# STM32WB05 register map
File version: 1.0
CPU: CM0+ r0p0, little endian, MPU, no FPU, 2 interrupt priority bits
Registers are 32-bit, read-write, reset 0x0 unless marked. A register's access mark holds for its fields unless they carry their own. Offsets are from the block's base; [hi:lo] are bit positions; {n}, {i} and the like mark numbered series.

## DMAMUX
Base 0x48800000
{0x0+4i} C{i}CR (i=0..7) (reset mask 0xF) — CxCR register
  [4:0] DMAREQ_ID — DMAREQ_ID[4:0]: DMA REQuest IDentification Selects the input DMA request. C.f. the DMAMUX table about assignments of multiplexer inputs to resources.
    2=Spi3Rx; 3=Spi3Tx; 8=I2c1Rx; 9=I2c1Tx; 12=UsartRx; 13=UsartTx; 14=LpuartRx; 15=LpuartTx; 16=ADC_CH0 (DS channel); {v}=Tim2Ch{v-17} (v=18..21); 22=Tim2Up; 23=Tim16Ch1; 24=Tim16Up; 25=Tim17Ch1; 26=Tim17Up

## GPIOA
Base 0x48000000
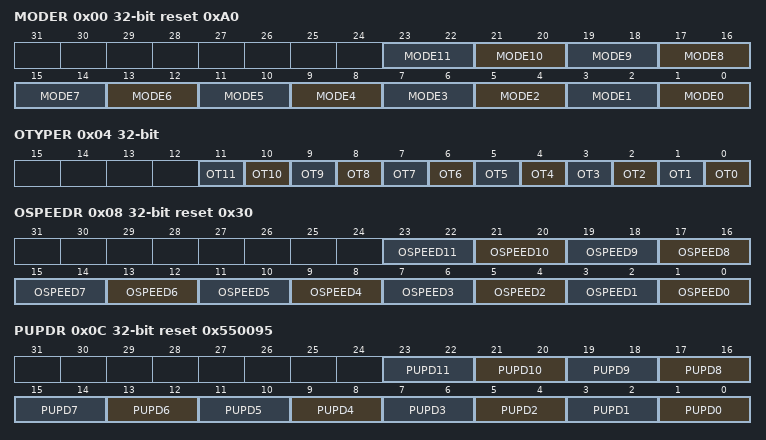
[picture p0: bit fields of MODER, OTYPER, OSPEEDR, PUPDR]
0x00 MODER reset 0xA0
  [2n+1:2n] MODE{n} (n=0..11) — Port x configuration pin {n}
    0=Input mode; 1=Output (General purpose output mode); 2=Alternate function mode; 3=Analog mode
0x04 OTYPER
  [n] OT{n} (n=0..11) — Port x configuration pin {n}
    0=PushPull (Output push-pull (reset state)); 1=OpenDrain (Output open-drain)
0x08 OSPEEDR reset 0x30
  [2n+1:2n] OSPEED{n} (n=0..11) — Port x configuration pin {n}
    0=LowSpeed; 1=MediumSpeed; 2=HighSpeed; 3=VeryHighSpeed
0x0C PUPDR reset 0x550095
  [2n+1:2n] PUPD{n} (n=0..11) — Port x configuration pin {n}
    0=Floating (No pull-up, pull-down); 1=PullUp; 2=PullDown
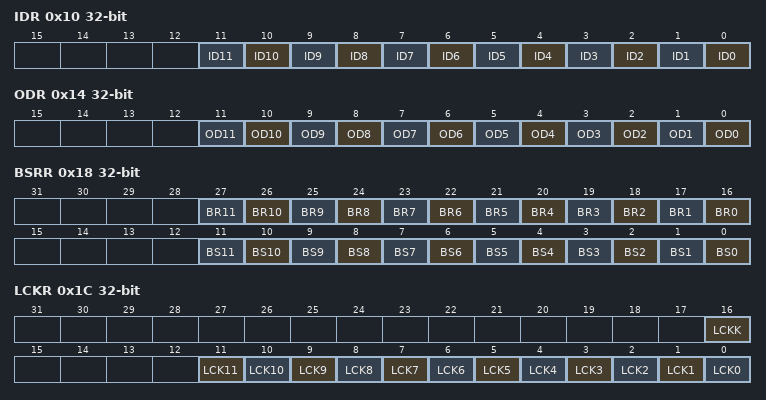
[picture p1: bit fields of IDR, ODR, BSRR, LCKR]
0x10 IDR ro
  [n] ID{n} (n=0..11) — Port input data pin {n}
    0=Low (Input is logic low); 1=High (Input is logic high)
0x14 ODR
  [n] OD{n} (n=0..11) — Port output data pin {n}
    0=Low (Set output to logic low); 1=High (Set output to logic high)
0x18 BSRR
  [n+16] BR{n} (n=0..11) wo — Port x reset pin {n}
    1=Resets the corresponding ODx bit
  [n] BS{n} (n=0..11) wo — Port x set pin {n}
    1=Set (Sets the corresponding ODx bit)
0x1C LCKR
  [16] LCKK — LCKK: Lock key This bit can be read any time. It can only be modified using the lock key write sequence. -0: Port configuration lock key not active -1: Port configuration lock key active. The GPIOx_LCKR register is locked until the next MCU reset or peripheral reset. LOCK key write sequence: WR LCKR[16] = 1' + LCKR[15:0] WR LCKR[16] = 0' + LCKR[15:0] WR LCKR[16] = 1' + LCKR[15:0] RD LCKR RD LCKR[16] = 1' (this read operation is optional but it confirms that the lock is active) Note: During the LOCK key write sequence, the value of LCK[15:0] must not change. Any error in the lock sequence aborts the lock. After the first lock sequence on any bit of the port, any read access on the LCKK bit will return 1' until the next MCU reset or peripheral reset
    0=NotActive (Port configuration lock key not active); 1=Active (Port configuration lock key active)
  [n] LCK{n} (n=0..11) — Port x lock pin {n}
    0=Unlocked (Port configuration not locked); 1=Locked (Port configuration locked)
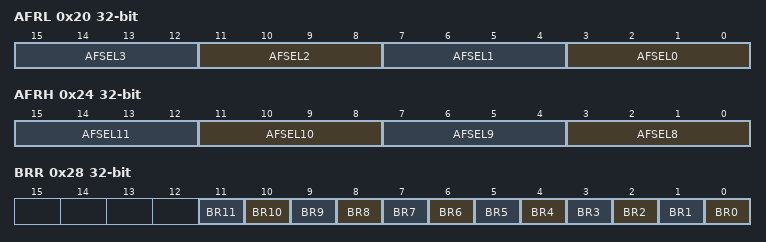
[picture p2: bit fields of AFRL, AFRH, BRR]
0x20 AFRL
  [4n+3:4n] AFSEL{n} (n=0..3) — y[3:0]: Alternate function selection for port A pin y (y = 0..7) These bits are written by software to configure alternate function I/Os AFSELy selection: -0000: AF0 -0001: AF1 -0010: AF2 -0011: AF3 -0100: AF4 -0101: AF5 -0110: AF6 -0111: AF7 1xxx: Reserved
    {v}=AF{v} (v=0..15)
0x24 AFRH
  [4n-29:4n-32] AFSEL{n} (n=8..11) — y[3:0]: Alternate function selection for port A pin y (y = 8..15) These bits are written by software to configure alternate function I/Os AFSELy selection: -0000: AF0 -0001: AF1 -0010: AF2 -0011: AF3 -0100: AF4 -0101: AF5 -0110: AF6 -0111: AF7 1xxx: Reserved
    {v}=AF{v} (v=0..15)
0x28 BRR
  [n] BR{n} (n=0..11) wo — Port x reset pin {n}
    0=No action on the corresponding ODx bit; 1=Reset the ODx bit

## GPIOB
Base 0x48100000
Registers as GPIOA; these are added or differ:
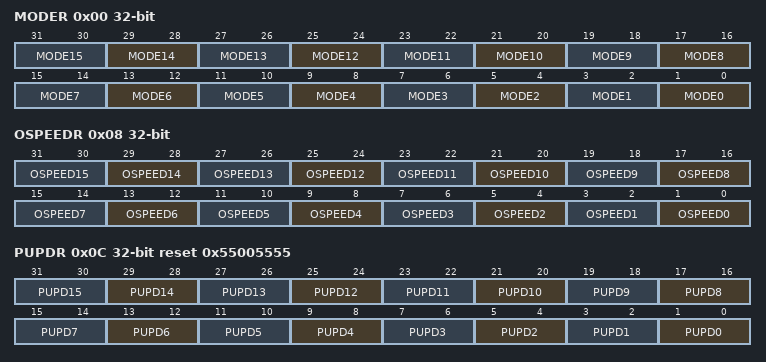
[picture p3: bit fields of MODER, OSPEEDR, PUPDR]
0x00 MODER
  [2n+1:2n] MODE{n} (n=0..15) — Port x configuration pin {n}
    0=Input mode; 1=Output (General purpose output mode); 2=Alternate function mode; 3=Analog mode
0x08 OSPEEDR
  [2n+1:2n] OSPEED{n} (n=0..15) — Port x configuration pin {n}
    0=LowSpeed; 1=MediumSpeed; 2=HighSpeed; 3=VeryHighSpeed
0x0C PUPDR reset 0x55005555
  [2n+1:2n] PUPD{n} (n=0..15) — Port x configuration pin {n}
    0=Floating (No pull-up, pull-down); 1=PullUp; 2=PullDown
